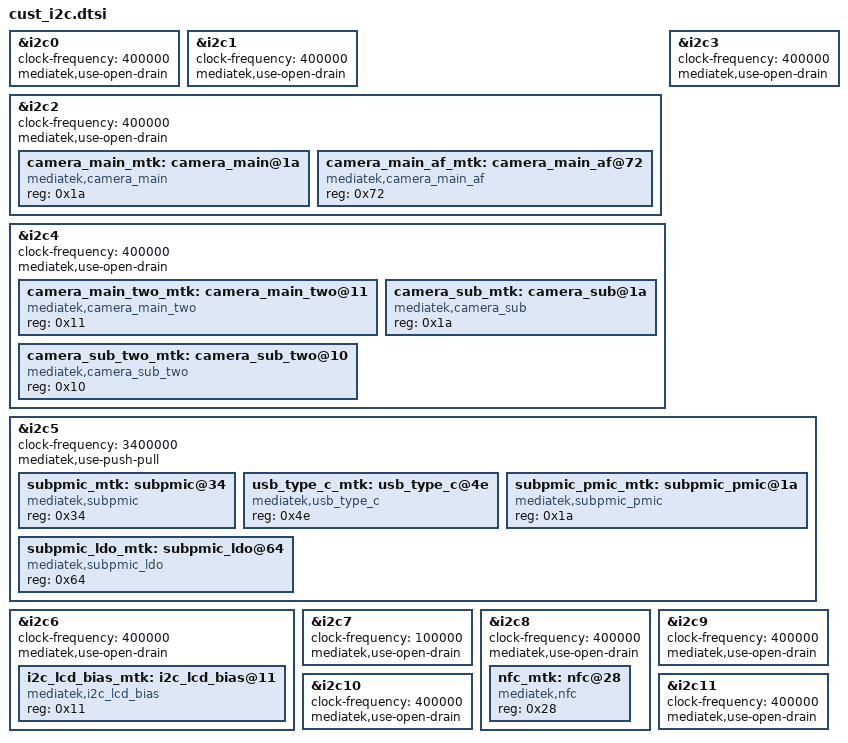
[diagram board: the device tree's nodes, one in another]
/*
 * Generated by MTK SP DrvGen Version: 3.5.160809 for MT6877.
 * 2023-12-12 19:21:58
 * Do Not Modify The File.
 * Copyright Mediatek Inc. (c) 2016.
*/

/*************************
 * I2C DTSI File
*************************/

&i2c0 {
	#address-cells = <1>;
	#size-cells = <0>;
	clock-frequency = <400000>;
	mediatek,use-open-drain;
};

&i2c1 {
	#address-cells = <1>;
	#size-cells = <0>;
	clock-frequency = <400000>;
	mediatek,use-open-drain;
};

&i2c2 {
	#address-cells = <1>;
	#size-cells = <0>;
	clock-frequency = <400000>;
	mediatek,use-open-drain;
	camera_main_mtk:camera_main@1a {
		compatible = "mediatek,camera_main";
		reg = <0x1a>;
		status = "okay";
	};

	camera_main_af_mtk:camera_main_af@72 {
		compatible = "mediatek,camera_main_af";
		reg = <0x72>;
		status = "okay";
	};

};

&i2c3 {
	#address-cells = <1>;
	#size-cells = <0>;
	clock-frequency = <400000>;
	mediatek,use-open-drain;
};

&i2c4 {
	#address-cells = <1>;
	#size-cells = <0>;
	clock-frequency = <400000>;
	mediatek,use-open-drain;
	camera_main_two_mtk:camera_main_two@11 {
		compatible = "mediatek,camera_main_two";
		reg = <0x11>;
		status = "okay";
	};

	camera_sub_mtk:camera_sub@1a {
		compatible = "mediatek,camera_sub";
		reg = <0x1a>;
		status = "okay";
	};

	camera_sub_two_mtk:camera_sub_two@10 {
		compatible = "mediatek,camera_sub_two";
		reg = <0x10>;
		status = "okay";
	};

};

&i2c5 {
	#address-cells = <1>;
	#size-cells = <0>;
	clock-frequency = <3400000>;
	mediatek,use-push-pull;
	subpmic_mtk:subpmic@34 {
		compatible = "mediatek,subpmic";
		reg = <0x34>;
		status = "okay";
	};

	usb_type_c_mtk:usb_type_c@4e {
		compatible = "mediatek,usb_type_c";
		reg = <0x4e>;
		status = "okay";
	};

	subpmic_pmic_mtk:subpmic_pmic@1a {
		compatible = "mediatek,subpmic_pmic";
		reg = <0x1a>;
		status = "okay";
	};

	subpmic_ldo_mtk:subpmic_ldo@64 {
		compatible = "mediatek,subpmic_ldo";
		reg = <0x64>;
		status = "okay";
	};

};

&i2c6 {
	#address-cells = <1>;
	#size-cells = <0>;
	clock-frequency = <400000>;
	mediatek,use-open-drain;
	i2c_lcd_bias_mtk:i2c_lcd_bias@11 {
		compatible = "mediatek,i2c_lcd_bias";
		reg = <0x11>;
		status = "okay";
	};

};

&i2c7 {
	#address-cells = <1>;
	#size-cells = <0>;
	clock-frequency = <100000>;
	mediatek,use-open-drain;
};

&i2c8 {
	#address-cells = <1>;
	#size-cells = <0>;
	clock-frequency = <400000>;
	mediatek,use-open-drain;
	nfc_mtk:nfc@28 {
		compatible = "mediatek,nfc";
		reg = <0x28>;
		status = "okay";
	};

};

&i2c9 {
	#address-cells = <1>;
	#size-cells = <0>;
	clock-frequency = <400000>;
	mediatek,use-open-drain;
};

&i2c10 {
	#address-cells = <1>;
	#size-cells = <0>;
	clock-frequency = <400000>;
	mediatek,use-open-drain;
};

&i2c11 {
	#address-cells = <1>;
	#size-cells = <0>;
	clock-frequency = <400000>;
	mediatek,use-open-drain;
};

